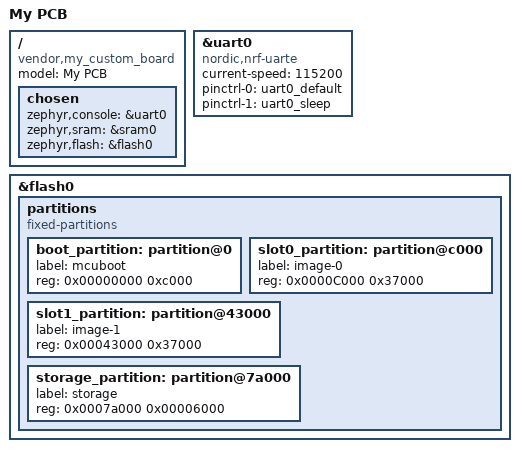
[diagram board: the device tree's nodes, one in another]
/dts-v1/;
#include <nordic/nrf52832_qfaa.dtsi>
#include "my_custom_board-pinctrl.dtsi"

/ {
    model = "My PCB";
    compatible = "vendor,my_custom_board";

    chosen {
      zephyr,console = &uart0;
      zephyr,sram = &sram0;
      zephyr,flash = &flash0;
    };
};

&uart0 {
  status = "okay";
  compatible = "nordic,nrf-uarte";
  current-speed = <115200>;
  pinctrl-0 = <&uart0_default>;
  pinctrl-1 = <&uart0_sleep>;
  pinctrl-names = "default", "sleep";
};

&flash0 {
  partitions {
    compatible = "fixed-partitions";
    #address-cells = <1>;
    #size-cells = <1>;

    boot_partition: partition@0 {
      label = "mcuboot";
      reg = <0x00000000 0xc000>;
    };
    slot0_partition: partition@c000 {
      label = "image-0";
      reg = <0x0000C000 0x37000>;
    };
    slot1_partition: partition@43000 {
      label = "image-1";
      reg = <0x00043000 0x37000>;
    };
    storage_partition: partition@7a000 {
      label = "storage";
      reg = <0x0007a000 0x00006000>;
      };
  };
};
